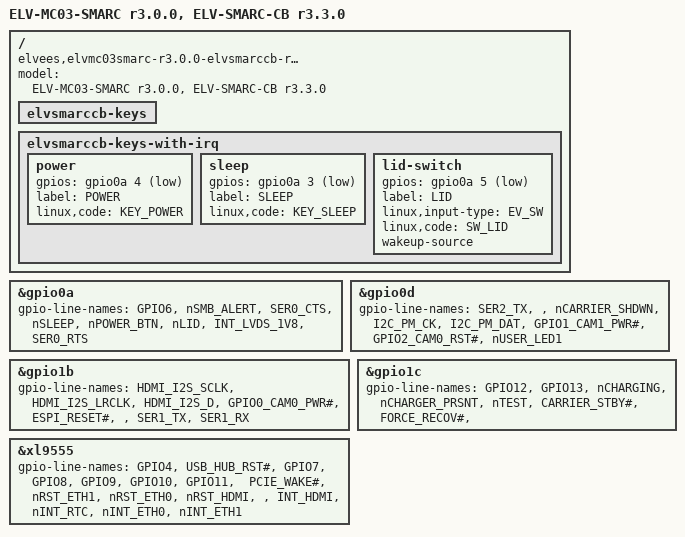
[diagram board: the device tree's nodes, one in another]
// SPDX-License-Identifier: GPL-2.0+
// Copyright 2025 RnD Center "ELVEES", JSC

/dts-v1/;

#include "mcom03-elvmc03smarc-r2.11.0-elvsmarccb-r3.3.0.dts"

/ {
	model = "ELV-MC03-SMARC r3.0.0, ELV-SMARC-CB r3.3.0";
	compatible = "elvees,elvmc03smarc-r3.0.0-elvsmarccb-r3.3.0",
		     "elvees,elvmc03smarc-elvsmarccb",
		     "elvees,elvsmarccb-r3.3.0",
		     "elvees,elvsmarccb",
		     "elvees,elvmc03smarc-r3.0.0",
		     "elvees,elvmc03smarc",
		     "elvees,mcom03";

	elvsmarccb-keys {
		/delete-node/ power;
		/delete-node/ sleep;
	};

	elvsmarccb-keys-with-irq {
		power {
			gpios = <&gpio0a 4 GPIO_ACTIVE_LOW>;
			label = "POWER";
			linux,code = <KEY_POWER>;
		};

		sleep {
			gpios = <&gpio0a 3 GPIO_ACTIVE_LOW>;
			label = "SLEEP";
			linux,code = <KEY_SLEEP>;
		};

		lid-switch {
			gpios = <&gpio0a 5 GPIO_ACTIVE_LOW>;
			label = "LID";
			linux,input-type = <EV_SW>;
			linux,code = <SW_LID>;
			wakeup-source;
		};
	};
};

&gpio0a {
	gpio-line-names = "GPIO6", "nSMB_ALERT", "SER0_CTS", "nSLEEP",
		"nPOWER_BTN", "nLID", "INT_LVDS_1V8", "SER0_RTS";
};

&gpio0d {
	gpio-line-names = "SER2_TX", "", "nCARRIER_SHDWN", "I2C_PM_CK",
		"I2C_PM_DAT", "GPIO1_CAM1_PWR#", "GPIO2_CAM0_RST#", "nUSER_LED1";
};

&gpio1b {
	gpio-line-names = "HDMI_I2S_SCLK", "HDMI_I2S_LRCLK", "HDMI_I2S_D",
		"GPIO0_CAM0_PWR#", "ESPI_RESET#", "", "SER1_TX", "SER1_RX";
};

&gpio1c {
	gpio-line-names = "GPIO12", "GPIO13", "nCHARGING", "nCHARGER_PRSNT",
		"nTEST", "CARRIER_STBY#", "FORCE_RECOV#", "";
};

&xl9555 {
	gpio-line-names = "GPIO4", "USB_HUB_RST#", "GPIO7", "GPIO8", "GPIO9",
		"GPIO10", "GPIO11", " PCIE_WAKE#", "nRST_ETH1", "nRST_ETH0",
		"nRST_HDMI", "", "INT_HDMI", "nINT_RTC", "nINT_ETH0", "nINT_ETH1";
};
